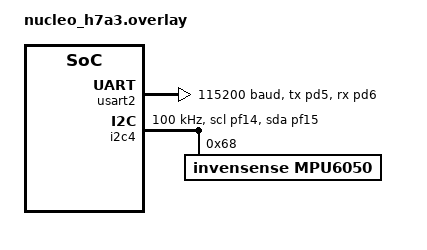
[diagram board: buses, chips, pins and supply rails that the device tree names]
/ {
	chosen {
		zephyr,console = &usart2;
		zephyr,shell-uart = &usart2;
	};
	
	aliases {
		imu-lower-joint = &mpu6050;
	};
};

&usart2 {
	pinctrl-0 = <&usart2_tx_pd5 &usart2_rx_pd6>;
	pinctrl-names = "default";
	current-speed = <115200>;
	status = "okay";
};

&i2c4 {
	status = "okay";
	pinctrl-0  = <&i2c4_scl_pf14 &i2c4_sda_pf15>;
	pinctrl-names = "default";
	clock-frequency = <I2C_BITRATE_STANDARD>;
	mpu6050: mpu6050@68 {
		compatible = "invensense,mpu6050";
		reg = <0x68>;
		status = "okay";
	};
};
